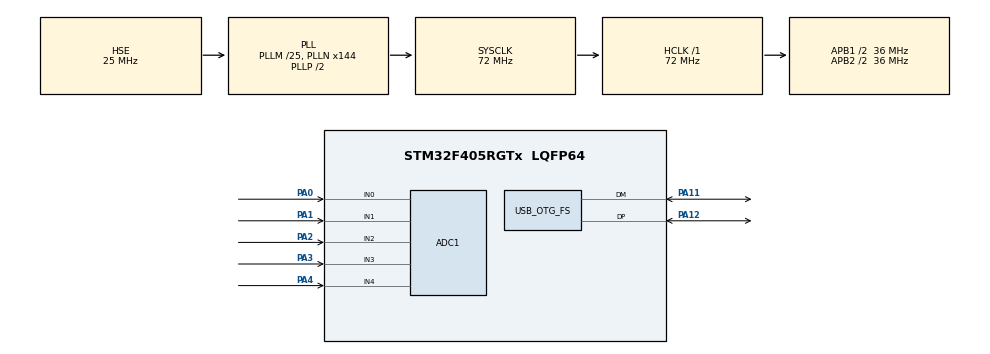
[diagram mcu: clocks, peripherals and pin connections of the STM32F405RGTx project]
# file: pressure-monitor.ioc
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ADC1.Channel-0\#ChannelRegularConversion=ADC_CHANNEL_0
ADC1.ContinuousConvMode=ENABLE
ADC1.NbrOfConversionFlag=1
ADC1.Rank-0\#ChannelRegularConversion=1
ADC1.SamplingTime-0\#ChannelRegularConversion=ADC_SAMPLETIME_3CYCLES
ADC1.ScanConvMode=ENABLE
ADC1.master=1
Dma.ADC1.0.Direction=DMA_PERIPH_TO_MEMORY
Dma.ADC1.0.FIFOMode=DMA_FIFOMODE_DISABLE
Dma.ADC1.0.Instance=DMA2_Stream0
Dma.ADC1.0.MemDataAlignment=DMA_MDATAALIGN_HALFWORD
Dma.ADC1.0.MemInc=DMA_MINC_ENABLE
Dma.ADC1.0.Mode=DMA_CIRCULAR
Dma.ADC1.0.PeriphDataAlignment=DMA_PDATAALIGN_HALFWORD
Dma.ADC1.0.PeriphInc=DMA_PINC_DISABLE
Dma.ADC1.0.Priority=DMA_PRIORITY_LOW
Dma.Request0=ADC1
Mcu.Family=STM32F4
Mcu.Name=STM32F405RGTx
Mcu.Package=LQFP64
NVIC.DMA2_Stream0_IRQn=true\:0\:0\:false\:false\:true\:false\:true\:true
NVIC.OTG_FS_IRQn=true\:0\:0\:false\:false\:true\:false\:true\:true
NVIC.PriorityGroup=NVIC_PRIORITYGROUP_4
PA0-WKUP.Signal=ADCx_IN0
PA1.Signal=ADCx_IN1
PA11.Mode=Device_Only
PA11.Signal=USB_OTG_FS_DM
PA12.Mode=Device_Only
PA12.Signal=USB_OTG_FS_DP
PA2.Signal=ADCx_IN2
PA3.Signal=ADCx_IN3
PA4.Signal=ADCx_IN4
PC14-OSC32_IN.Mode=LSE-External-Clock-Source
PC14-OSC32_IN.Signal=RCC_OSC32_IN
PC15-OSC32_OUT.Mode=LSE-External-Clock-Source
PC15-OSC32_OUT.Signal=RCC_OSC32_OUT
PH0-OSC_IN.Mode=HSE-External-Clock-Source
PH0-OSC_IN.Signal=RCC_OSC_IN
PH1-OSC_OUT.Mode=HSE-External-Clock-Source
PH1-OSC_OUT.Signal=RCC_OSC_OUT
ProjectManager.HeapSize=0x200
ProjectManager.StackSize=0x400
ProjectManager.TargetToolchain=MDK-ARM V5.32
RCC.48MHZClocksFreq_Value=48000000
RCC.AHBFreq_Value=72000000
RCC.APB1CLKDivider=RCC_HCLK_DIV2
RCC.APB1Freq_Value=36000000
RCC.APB1TimFreq_Value=72000000
RCC.APB2CLKDivider=RCC_HCLK_DIV2
RCC.APB2Freq_Value=36000000
RCC.APB2TimFreq_Value=72000000
RCC.CortexFreq_Value=72000000
RCC.HCLKFreq_Value=72000000
RCC.HSE_VALUE=25000000
RCC.HSI_VALUE=16000000
RCC.LSE_VALUE=32768
RCC.PLLM=25
RCC.PLLN=144
RCC.PLLQ=3
RCC.SYSCLKFreq_VALUE=72000000
RCC.SYSCLKSource=RCC_SYSCLKSOURCE_PLLCLK
RCC.VCOOutputFreq_Value=144000000
SH.ADCx_IN0.0=ADC1_IN0,IN0
SH.ADCx_IN1.0=ADC1_IN1,IN1
SH.ADCx_IN2.0=ADC1_IN2,IN2
SH.ADCx_IN3.0=ADC1_IN3,IN3
SH.ADCx_IN4.0=ADC1_IN4,IN4
USB_DEVICE.CLASS_NAME_FS=CDC
USB_DEVICE.VirtualMode-CDC_FS=Cdc
USB_DEVICE.VirtualModeFS=Cdc_FS
USB_OTG_FS.VirtualMode=Device_Only
VP_USB_DEVICE_VS_USB_DEVICE_CDC_FS.Mode=CDC_FS
board=custom

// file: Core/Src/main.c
/* USER CODE BEGIN Header */
/**
  ******************************************************************************
  * @file           : main.c
  * @brief          : Main program body
  ******************************************************************************
  * @attention
  *
  * Copyright (c) 2025 STMicroelectronics.
  * All rights reserved.
  *
  * This software is licensed under terms that can be found in the LICENSE file
  * in the root directory of this software component.
  * If no LICENSE file comes with this software, it is provided AS-IS.
  *
  ******************************************************************************
  */
/* USER CODE END Header */
#include "main.h"
#include "adc.h"
#include "dma.h"
#include "usb_device.h"
#include "gpio.h"

/* USER CODE BEGIN Includes */
#include "usbd_conf.h"
/* USER CODE END Includes */

void SystemClock_Config(void);
/* USER CODE BEGIN PFP */
uint16_t adc_buffer[5];
void HAL_ADC_ConvCpltCallback(ADC_HandleTypeDef* hadc)
{
  /* Prevent unused argument(s) compilation warning */
  if (HAL_ADC_Start_DMA(hadc,(uint32_t *)adc_buffer,10) != HAL_OK)//????ADC DMA???
  {
    /* ADC conversion start error */
    Error_Handler();
  }

  /* NOTE : This function should not be modified. When the callback is needed,
            function HAL_ADC_ConvCpltCallback must be implemented in the user file.
   */
}
/* USER CODE END PFP */

int main(void)
{

  /* MCU Configuration--------------------------------------------------------*/

  /* Reset of all peripherals, Initializes the Flash interface and the Systick. */
  HAL_Init();

  /* Configure the system clock */
  SystemClock_Config();

  /* Initialize all configured peripherals */
  MX_GPIO_Init();
  MX_DMA_Init();
  MX_USB_DEVICE_Init();
  MX_ADC1_Init();
  /* USER CODE BEGIN 2 */

  if(HAL_ADCEx_Calibration_Start(&hadc1) != HAL_OK)
	{
		Error_Handler();
	}
	if(HAL_ADC_Start_DMA(&hadc1,(uint32_t*)adc_buffer,4)!=HAL_OK)
	{
		Error_Handler();
	}
  /* USER CODE END 2 */

  /* Infinite loop */
  while (1)
  {

  }
}

void SystemClock_Config(void)
{
  RCC_OscInitTypeDef RCC_OscInitStruct = {0};
  RCC_ClkInitTypeDef RCC_ClkInitStruct = {0};

  /** Configure the main internal regulator output voltage
  */
  __HAL_RCC_PWR_CLK_ENABLE();
  __HAL_PWR_VOLTAGESCALING_CONFIG(PWR_REGULATOR_VOLTAGE_SCALE1);

  /** Initializes the RCC Oscillators according to the specified parameters
  * in the RCC_OscInitTypeDef structure.
  */
  RCC_OscInitStruct.OscillatorType = RCC_OSCILLATORTYPE_HSE;
  RCC_OscInitStruct.HSEState = RCC_HSE_BYPASS;
  RCC_OscInitStruct.PLL.PLLState = RCC_PLL_ON;
  RCC_OscInitStruct.PLL.PLLSource = RCC_PLLSOURCE_HSE;
  RCC_OscInitStruct.PLL.PLLM = 25;
  RCC_OscInitStruct.PLL.PLLN = 144;
  RCC_OscInitStruct.PLL.PLLP = RCC_PLLP_DIV2;
  RCC_OscInitStruct.PLL.PLLQ = 3;
  if (HAL_RCC_OscConfig(&RCC_OscInitStruct) != HAL_OK)
  {
    Error_Handler();
  }

  /** Initializes the CPU, AHB and APB buses clocks
  */
  RCC_ClkInitStruct.ClockType = RCC_CLOCKTYPE_HCLK|RCC_CLOCKTYPE_SYSCLK
                              |RCC_CLOCKTYPE_PCLK1|RCC_CLOCKTYPE_PCLK2;
  RCC_ClkInitStruct.SYSCLKSource = RCC_SYSCLKSOURCE_PLLCLK;
  RCC_ClkInitStruct.AHBCLKDivider = RCC_SYSCLK_DIV1;
  RCC_ClkInitStruct.APB1CLKDivider = RCC_HCLK_DIV2;
  RCC_ClkInitStruct.APB2CLKDivider = RCC_HCLK_DIV2;

  if (HAL_RCC_ClockConfig(&RCC_ClkInitStruct, FLASH_LATENCY_2) != HAL_OK)
  {
    Error_Handler();
  }
}

void Error_Handler(void)
{
  __disable_irq();
  while (1)
  {
  }
}
